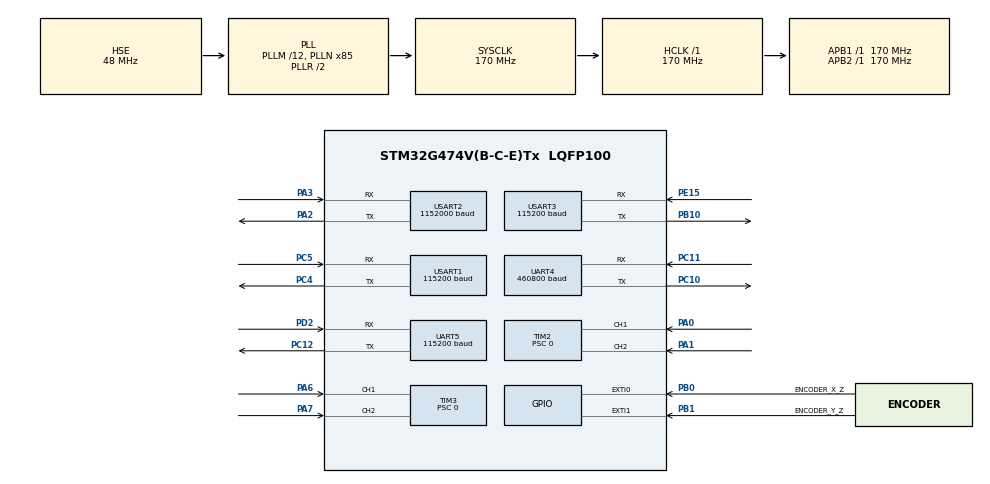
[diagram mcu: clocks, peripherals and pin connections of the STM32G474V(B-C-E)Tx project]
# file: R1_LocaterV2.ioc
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FREERTOS.Tasks01=TaskLocater,24,512,StartLocaterTask,Default,NULL,Dynamic,NULL,NULL;TaskTelemetry,8,512,StartTelemetryTask,Default,NULL,Dynamic,NULL,NULL;TaskDT35,8,512,StartDT35Task,Default,NULL,Dynamic,NULL,NULL
FREERTOS.configTOTAL_HEAP_SIZE=32768
FREERTOS.configUSE_NEWLIB_REENTRANT=1
Mcu.Family=STM32G4
Mcu.Name=STM32G474V(B-C-E)Tx
Mcu.Package=LQFP100
NVIC.EXTI0_IRQn=true\:5\:0\:false\:false\:true\:true\:true\:true\:true
NVIC.EXTI1_IRQn=true\:5\:0\:false\:false\:true\:true\:true\:true\:true
NVIC.PriorityGroup=NVIC_PRIORITYGROUP_4
NVIC.TIM6_DAC_IRQn=true\:15\:0\:false\:false\:true\:false\:false\:true\:true
NVIC.TimeBase=TIM6_DAC_IRQn
NVIC.TimeBaseIP=TIM6
NVIC.UART4_IRQn=true\:5\:0\:false\:false\:true\:true\:false\:true\:true
NVIC.UART5_IRQn=true\:5\:0\:false\:false\:true\:true\:false\:true\:true
NVIC.USART1_IRQn=true\:5\:0\:false\:false\:true\:true\:false\:true\:true
NVIC.USART2_IRQn=true\:5\:0\:false\:false\:true\:true\:false\:true\:true
NVIC.USART3_IRQn=true\:5\:0\:false\:false\:true\:true\:false\:true\:true
PA2.Mode=Asynchronous
PA2.Signal=USART2_TX
PA3.Mode=Asynchronous
PA3.Signal=USART2_RX
PB10.Mode=Asynchronous
PB10.Signal=USART3_TX
PE15.Mode=Asynchronous
PE15.Signal=USART3_RX
PC4.Mode=Asynchronous
PC4.Signal=USART1_TX
PC5.Mode=Asynchronous
PC5.Signal=USART1_RX
PC10.Mode=Asynchronous
PC10.Signal=UART4_TX
PC11.Mode=Asynchronous
PC11.Signal=UART4_RX
PC12.Mode=Asynchronous
PC12.Signal=UART5_TX
PD2.Mode=Asynchronous
PD2.Signal=UART5_RX
UART5.BaudRate=115200
UART5.VirtualMode-Asynchronous=VM_ASYNC
USART1.BaudRate=115200
USART1.VirtualMode-Asynchronous=VM_ASYNC
USART2.BaudRate=1152000
USART2.VirtualMode-Asynchronous=VM_ASYNC
USART3.BaudRate=115200
USART3.VirtualMode-Asynchronous=VM_ASYNC
PA0.Mode=Encoder_Interface
PA0.Signal=TIM2_CH1
PA1.Mode=Encoder_Interface
PA1.Signal=TIM2_CH2
PA6.Mode=Encoder_Interface
PA6.Signal=TIM3_CH1
PA7.Mode=Encoder_Interface
PA7.Signal=TIM3_CH2
PA13.Mode=Serial_Wire
PA13.Signal=SYS_JTMS-SWDIO
PA14.Mode=Serial_Wire
PA14.Signal=SYS_JTCK-SWCLK
PB0.GPIO_Label=ENCODER_X_Z
PB0.Signal=GPXTI0
PB1.GPIO_Label=ENCODER_Y_Z
PB1.Signal=GPXTI1
PF0-OSC_IN.Mode=HSE-External-Oscillator
PF0-OSC_IN.Signal=RCC_OSC_IN
PF1-OSC_OUT.Mode=HSE-External-Oscillator
PF1-OSC_OUT.Signal=RCC_OSC_OUT
ProjectManager.HeapSize=0x200
ProjectManager.StackSize=0x400
ProjectManager.TargetToolchain=STM32CubeIDE
RCC.ADC12Freq_Value=170000000
RCC.ADC345Freq_Value=170000000
RCC.AHBFreq_Value=170000000
RCC.APB1Freq_Value=170000000
RCC.APB1TimFreq_Value=170000000
RCC.APB2Freq_Value=170000000
RCC.APB2TimFreq_Value=170000000
RCC.CortexFreq_Value=170000000
RCC.EXTERNAL_CLOCK_VALUE=12288000
RCC.HCLKFreq_Value=170000000
RCC.HSE_VALUE=48000000
RCC.HSI48_VALUE=48000000
RCC.HSI_VALUE=16000000
RCC.LSE_VALUE=32768
RCC.PLLM=RCC_PLLM_DIV12
RCC.PLLN=85
RCC.PLLSourceVirtual=RCC_PLLSOURCE_HSE
RCC.SYSCLKFreq_VALUE=170000000
RCC.SYSCLKSource=RCC_SYSCLKSOURCE_PLLCLK
RCC.USBFreq_Value=170000000
RCC.VCOOutputFreq_Value=340000000
TIM2.Channel-Encoder\ Mode=TIM_CHANNEL_ENCODER
TIM2.EncoderMode=TIM_ENCODERMODE_TI12
TIM2.PeriodNoDither=4294967295
TIM2.Prescaler=0
TIM3.Channel-Encoder\ Mode=TIM_CHANNEL_ENCODER
TIM3.EncoderMode=TIM_ENCODERMODE_TI12
TIM3.PeriodNoDither=65535
TIM3.Prescaler=0
UART4.BaudRate=460800
UART4.VirtualMode-Asynchronous=VM_ASYNC
VP_FREERTOS_VS_CMSIS_V2.Mode=CMSIS_V2
VP_SYS_VS_DBSignals.Mode=DisableDeadBatterySignals
VP_SYS_VS_tim6.Mode=TIM6
board=custom

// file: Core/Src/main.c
/* USER CODE BEGIN Header */
/**
  ******************************************************************************
  * @file           : main.c
  * @brief          : Main program body
  ******************************************************************************
  */
/* USER CODE END Header */

#include "main.h"
#include "cmsis_os.h"
#include "tim.h"
#include "usart.h"
#include "gpio.h"
#include "driver_encoder.h"
#include "locater_config.h"

void SystemClock_Config(void);
void MX_FREERTOS_Init(void);

#if LOCATER_USART1_BOOT_TEST_ENABLE
static void USART1_BootTrace(uint32_t marker)
{
  static const uint8_t boot_111[] = "111.000,1.000,0.000,0.000,0.000\r\n";
  static const uint8_t boot_222[] = "222.000,2.000,0.000,0.000,0.000\r\n";
  static const uint8_t boot_333[] = "333.000,3.000,0.000,0.000,0.000\r\n";
  const uint8_t *frame = boot_111;
  uint16_t len = (uint16_t)(sizeof(boot_111) - 1U);

  if (marker == 222U) {
    frame = boot_222;
    len = (uint16_t)(sizeof(boot_222) - 1U);
  } else if (marker == 333U) {
    frame = boot_333;
    len = (uint16_t)(sizeof(boot_333) - 1U);
  }

  for (uint32_t i = 0U; i < 5U; i++) {
    (void)HAL_UART_Transmit(&huart1, (uint8_t *)frame, len, 100U);
  }
}
#endif

int main(void)
{
  HAL_Init();
  SystemClock_Config();

  MX_GPIO_Init();
  MX_USART1_UART_Init();
  MX_USART2_UART_Init();
  MX_USART3_UART_Init();
#if LOCATER_USART1_BOOT_TEST_ENABLE
  USART1_BootTrace(111U);
#endif
  MX_UART4_Init();
  MX_UART5_Init();
  MX_TIM2_Init();
  MX_TIM3_Init();
#if LOCATER_USART1_BOOT_TEST_ENABLE
  USART1_BootTrace(222U);
#endif

  osKernelInitialize();
  MX_FREERTOS_Init();
#if LOCATER_USART1_BOOT_TEST_ENABLE
  USART1_BootTrace(333U);
#endif
  osKernelStart();

  while (1)
  {
  }
}

void SystemClock_Config(void)
{
  RCC_OscInitTypeDef RCC_OscInitStruct = {0};
  RCC_ClkInitTypeDef RCC_ClkInitStruct = {0};

  HAL_PWREx_ControlVoltageScaling(PWR_REGULATOR_VOLTAGE_SCALE1_BOOST);

  RCC_OscInitStruct.OscillatorType = RCC_OSCILLATORTYPE_HSE;
  RCC_OscInitStruct.HSEState = RCC_HSE_ON;
  RCC_OscInitStruct.PLL.PLLState = RCC_PLL_ON;
  RCC_OscInitStruct.PLL.PLLSource = RCC_PLLSOURCE_HSE;
  RCC_OscInitStruct.PLL.PLLM = RCC_PLLM_DIV12;
  RCC_OscInitStruct.PLL.PLLN = 85;
  RCC_OscInitStruct.PLL.PLLP = RCC_PLLP_DIV2;
  RCC_OscInitStruct.PLL.PLLQ = RCC_PLLQ_DIV2;
  RCC_OscInitStruct.PLL.PLLR = RCC_PLLR_DIV2;
  if (HAL_RCC_OscConfig(&RCC_OscInitStruct) != HAL_OK)
  {
    Error_Handler();
  }

  RCC_ClkInitStruct.ClockType = RCC_CLOCKTYPE_HCLK|RCC_CLOCKTYPE_SYSCLK
                              |RCC_CLOCKTYPE_PCLK1|RCC_CLOCKTYPE_PCLK2;
  RCC_ClkInitStruct.SYSCLKSource = RCC_SYSCLKSOURCE_PLLCLK;
  RCC_ClkInitStruct.AHBCLKDivider = RCC_SYSCLK_DIV1;
  RCC_ClkInitStruct.APB1CLKDivider = RCC_HCLK_DIV1;
  RCC_ClkInitStruct.APB2CLKDivider = RCC_HCLK_DIV1;

  if (HAL_RCC_ClockConfig(&RCC_ClkInitStruct, FLASH_LATENCY_4) != HAL_OK)
  {
    Error_Handler();
  }
}

void HAL_TIM_PeriodElapsedCallback(TIM_HandleTypeDef *htim)
{
  if (htim->Instance == TIM6) {
    HAL_IncTick();
  }
}

void HAL_GPIO_EXTI_Callback(uint16_t GPIO_Pin)
{
  Driver_Encoder_EXTI_Callback(GPIO_Pin);
}

void Error_Handler(void)
{
#if LOCATER_USART1_BOOT_TEST_ENABLE
  if (huart1.Instance == USART1) {
    static const uint8_t error_frame[] = "999.000,9.000,0.000,0.000,0.000\r\n";
    for (uint32_t i = 0U; i < 5U; i++) {
      (void)HAL_UART_Transmit(&huart1, (uint8_t *)error_frame, (uint16_t)(sizeof(error_frame) - 1U), 100U);
    }
  }
#endif
  __disable_irq();
  while (1)
  {
  }
}

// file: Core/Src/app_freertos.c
/* USER CODE BEGIN Header */
/**
  ******************************************************************************
  * File Name          : app_freertos.c
  * Description        : FreeRTOS application tasks for R1_LocaterV2.
  ******************************************************************************
  */
/* USER CODE END Header */

#include "FreeRTOS.h"
#include "task.h"
#include "main.h"
#include "cmsis_os.h"

/* USER CODE BEGIN Includes */
extern void StartLocaterTask(void *argument);
extern void StartTelemetryTask(void *argument);
extern void StartDT35Task(void *argument);
/* USER CODE END Includes */

osThreadId_t TaskLocaterHandle;
const osThreadAttr_t TaskLocater_attributes = {
        .name = "TaskLocater",
        .stack_size = 768 * 4,
        .priority = (osPriority_t) osPriorityNormal,
};

osThreadId_t TaskTelemetryHandle;
const osThreadAttr_t TaskTelemetry_attributes = {
        .name = "TaskTelemetry",
        .stack_size = 768 * 4,
        .priority = (osPriority_t) osPriorityLow,
};

osThreadId_t TaskDT35Handle;
const osThreadAttr_t TaskDT35_attributes = {
        .name = "TaskDT35",
        .stack_size = 512 * 4,
        .priority = (osPriority_t) osPriorityLow,
};

void MX_FREERTOS_Init(void)
{
    TaskLocaterHandle = osThreadNew(StartLocaterTask, NULL, &TaskLocater_attributes);
    TaskTelemetryHandle = osThreadNew(StartTelemetryTask, NULL, &TaskTelemetry_attributes);
    TaskDT35Handle = osThreadNew(StartDT35Task, NULL, &TaskDT35_attributes);
}
